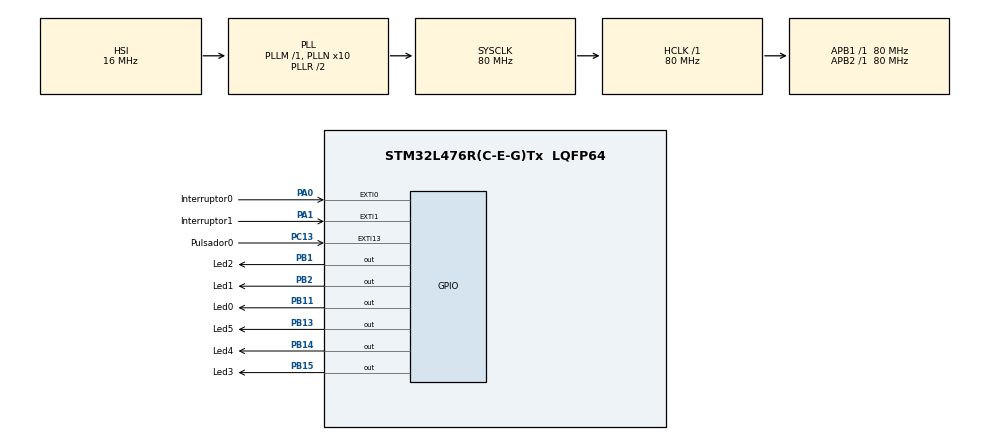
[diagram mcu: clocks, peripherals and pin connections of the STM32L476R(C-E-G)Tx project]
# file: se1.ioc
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Mcu.Family=STM32L4
Mcu.Name=STM32L476R(C-E-G)Tx
Mcu.Package=LQFP64
NVIC.EXTI0_IRQn=true\:0\:0\:false\:false\:true\:true\:true\:true
NVIC.EXTI15_10_IRQn=true\:0\:0\:false\:false\:true\:true\:true\:true
NVIC.EXTI1_IRQn=true\:0\:0\:false\:false\:true\:true\:true\:true
NVIC.PriorityGroup=NVIC_PRIORITYGROUP_4
NVIC.TIM6_DAC_IRQn=true\:0\:0\:false\:false\:true\:true\:true\:true
PA0.GPIO_Label=Interruptor0
PA0.GPIO_ModeDefaultEXTI=GPIO_MODE_IT_RISING_FALLING
PA0.Signal=GPXTI0
PA1.GPIO_Label=Interruptor1
PA1.GPIO_ModeDefaultEXTI=GPIO_MODE_IT_RISING_FALLING
PA1.Signal=GPXTI1
PA13\ (JTMS-SWDIO).GPIO_Label=TMS
PA13\ (JTMS-SWDIO).Signal=SYS_JTMS-SWDIO
PA14\ (JTCK-SWCLK).GPIO_Label=TCK
PA14\ (JTCK-SWCLK).Signal=SYS_JTCK-SWCLK
PA2.GPIO_Label=USART_TX
PA2.GPIO_Mode=GPIO_MODE_AF_PP
PA2.GPIO_PuPd=GPIO_NOPULL
PA2.GPIO_Speed=GPIO_SPEED_FREQ_VERY_HIGH
PA2.Signal=USART2_TX
PA3.GPIO_Label=USART_RX
PA3.GPIO_Mode=GPIO_MODE_AF_PP
PA3.GPIO_PuPd=GPIO_NOPULL
PA3.GPIO_Speed=GPIO_SPEED_FREQ_VERY_HIGH
PA3.Signal=USART2_RX
PB1.GPIO_Label=Led2
PB1.Signal=GPIO_Output
PB11.GPIO_Label=Led0
PB11.Signal=GPIO_Output
PB13.GPIO_Label=Led5
PB13.Signal=GPIO_Output
PB14.GPIO_Label=Led4
PB14.Signal=GPIO_Output
PB15.GPIO_Label=Led3
PB15.Signal=GPIO_Output
PB2.GPIO_Label=Led1
PB2.Signal=GPIO_Output
PB3\ (JTDO-TRACESWO).GPIO_Label=SWO
PB3\ (JTDO-TRACESWO).Signal=SYS_JTDO-SWO
PC13.GPIO_Label=Pulsador0
PC13.GPIO_ModeDefaultEXTI=GPIO_MODE_IT_FALLING
PC13.Signal=GPXTI13
PC14-OSC32_IN\ (PC14).Signal=RCC_OSC32_IN
PC15-OSC32_OUT\ (PC15).Signal=RCC_OSC32_OUT
PH0-OSC_IN\ (PH0).Signal=RCC_OSC_IN
PH1-OSC_OUT\ (PH1).Signal=RCC_OSC_OUT
ProjectManager.HeapSize=0x200
ProjectManager.StackSize=0x400
ProjectManager.TargetToolchain=STM32CubeIDE
RCC.ADCFreq_Value=64000000
RCC.AHBFreq_Value=80000000
RCC.APB1Freq_Value=80000000
RCC.APB1TimFreq_Value=80000000
RCC.APB2Freq_Value=80000000
RCC.APB2TimFreq_Value=80000000
RCC.CortexFreq_Value=80000000
RCC.HCLKFreq_Value=80000000
RCC.HSE_VALUE=8000000
RCC.HSI_VALUE=16000000
RCC.LSE_VALUE=32768
RCC.MSI_VALUE=4000000
RCC.PLLN=10
RCC.PLLSourceVirtual=RCC_PLLSOURCE_HSI
RCC.PREFETCH_ENABLE=1
RCC.SYSCLKFreq_VALUE=80000000
RCC.SYSCLKSource=RCC_SYSCLKSOURCE_PLLCLK
RCC.USBFreq_Value=64000000
RCC.VCOOutputFreq_Value=160000000
TIM2.Period=2147483648
TIM2.Prescaler=412
TIM6.Period=100
TIM6.Prescaler=20000-1
VP_TIM2_VS_ClockSourceINT.Mode=Internal
VP_TIM6_VS_ClockSourceINT.Mode=Enable_Timer
board=NUCLEO-L476RG

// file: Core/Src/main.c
/* USER CODE BEGIN Header */
/**
  ******************************************************************************
  * @file           : main.c
  * @brief          : Main program body
  ******************************************************************************
  * @attention
  *
  * Copyright (c) 2026 STMicroelectronics.
  * All rights reserved.
  *
  * This software is licensed under terms that can be found in the LICENSE file
  * in the root directory of this software component.
  * If no LICENSE file comes with this software, it is provided AS-IS.
  *
  ******************************************************************************
  */
/* USER CODE END Header */
#include "main.h"
#include "tim.h"
#include "gpio.h"

/* USER CODE BEGIN Includes */
#include "MaquinaDeEstado.h"
#include <stdlib.h>
/* USER CODE END Includes */

void SystemClock_Config(void);

int main(void)
{

  /* MCU Configuration--------------------------------------------------------*/

  /* Reset of all peripherals, Initializes the Flash interface and the Systick. */
  HAL_Init();

  /* Configure the system clock */
  SystemClock_Config();

  /* Initialize all configured peripherals */
  MX_GPIO_Init();
  MX_TIM6_Init();
  MX_TIM2_Init();
  /* USER CODE BEGIN 2 */
  HAL_TIM_Base_Start_IT(&htim6);
  HAL_TIM_Base_Start(&htim2);

  semillarda = __HAL_TIM_GET_COUNTER(&htim2);
  srand(semillarda);

  HAL_GPIO_ReadPin(Interruptor0_GPIO_Port, Interruptor0_Pin) ? BIT_SET(State1, 0) : BIT_CLEAR(State1, 0) ;
  HAL_GPIO_ReadPin(Interruptor1_GPIO_Port, Interruptor1_Pin) ? BIT_SET(State1, 1) : BIT_CLEAR(State1, 1) ;
  /* USER CODE END 2 */

  /* Infinite loop */
  while (1)
  {

    /* USER CODE BEGIN 3 */
	  //

	  Maquinon();
  }
  /* USER CODE END 3 */
}

void SystemClock_Config(void)
{
  RCC_OscInitTypeDef RCC_OscInitStruct = {0};
  RCC_ClkInitTypeDef RCC_ClkInitStruct = {0};

  /** Configure the main internal regulator output voltage
  */
  if (HAL_PWREx_ControlVoltageScaling(PWR_REGULATOR_VOLTAGE_SCALE1) != HAL_OK)
  {
    Error_Handler();
  }

  /** Initializes the RCC Oscillators according to the specified parameters
  * in the RCC_OscInitTypeDef structure.
  */
  RCC_OscInitStruct.OscillatorType = RCC_OSCILLATORTYPE_HSI;
  RCC_OscInitStruct.HSIState = RCC_HSI_ON;
  RCC_OscInitStruct.HSICalibrationValue = RCC_HSICALIBRATION_DEFAULT;
  RCC_OscInitStruct.PLL.PLLState = RCC_PLL_ON;
  RCC_OscInitStruct.PLL.PLLSource = RCC_PLLSOURCE_HSI;
  RCC_OscInitStruct.PLL.PLLM = 1;
  RCC_OscInitStruct.PLL.PLLN = 10;
  RCC_OscInitStruct.PLL.PLLP = RCC_PLLP_DIV7;
  RCC_OscInitStruct.PLL.PLLQ = RCC_PLLQ_DIV2;
  RCC_OscInitStruct.PLL.PLLR = RCC_PLLR_DIV2;
  if (HAL_RCC_OscConfig(&RCC_OscInitStruct) != HAL_OK)
  {
    Error_Handler();
  }

  /** Initializes the CPU, AHB and APB buses clocks
  */
  RCC_ClkInitStruct.ClockType = RCC_CLOCKTYPE_HCLK|RCC_CLOCKTYPE_SYSCLK
                              |RCC_CLOCKTYPE_PCLK1|RCC_CLOCKTYPE_PCLK2;
  RCC_ClkInitStruct.SYSCLKSource = RCC_SYSCLKSOURCE_PLLCLK;
  RCC_ClkInitStruct.AHBCLKDivider = RCC_SYSCLK_DIV1;
  RCC_ClkInitStruct.APB1CLKDivider = RCC_HCLK_DIV1;
  RCC_ClkInitStruct.APB2CLKDivider = RCC_HCLK_DIV1;

  if (HAL_RCC_ClockConfig(&RCC_ClkInitStruct, FLASH_LATENCY_4) != HAL_OK)
  {
    Error_Handler();
  }
}

void Error_Handler(void)
{
  __disable_irq();
  while (1)
  {
  }
}
